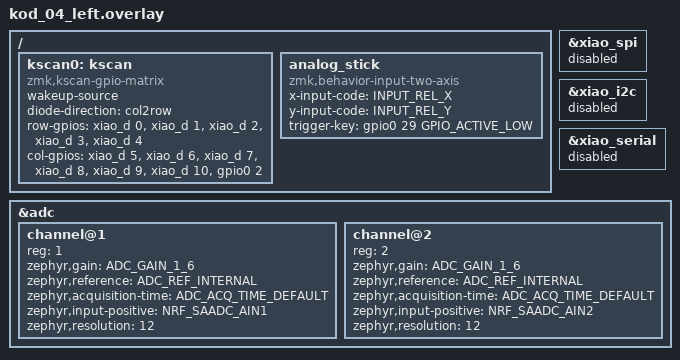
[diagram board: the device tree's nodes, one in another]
/*
 * Copyright (c) 2024 kodomari
 * SPDX-License-Identifier: MIT
 */

#include "kod_04.dtsi"

&xiao_spi { status = "disabled"; };
&xiao_i2c { status = "disabled"; };
&xiao_serial { status = "disabled"; };

/ {
    kscan0: kscan {
        compatible = "zmk,kscan-gpio-matrix";
        wakeup-source;
        diode-direction = "col2row";
        
        // 5行
        row-gpios
            = <&xiao_d 0 (GPIO_ACTIVE_HIGH | GPIO_PULL_DOWN)>
            , <&xiao_d 1 (GPIO_ACTIVE_HIGH | GPIO_PULL_DOWN)>
            , <&xiao_d 2 (GPIO_ACTIVE_HIGH | GPIO_PULL_DOWN)>
            , <&xiao_d 3 (GPIO_ACTIVE_HIGH | GPIO_PULL_DOWN)>
            , <&xiao_d 4 (GPIO_ACTIVE_HIGH | GPIO_PULL_DOWN)>
            ;
        
        // 7列
        col-gpios
            = <&xiao_d 5 GPIO_ACTIVE_HIGH>
            , <&xiao_d 6 GPIO_ACTIVE_HIGH>
            , <&xiao_d 7 GPIO_ACTIVE_HIGH>
            , <&xiao_d 8 GPIO_ACTIVE_HIGH>
            , <&xiao_d 9 GPIO_ACTIVE_HIGH>
            , <&xiao_d 10 GPIO_ACTIVE_HIGH>
            , <&gpio0 2 GPIO_ACTIVE_HIGH>  // P0.02 (A0/D0)
            ;
    };

    // アナログスティック（ジョイスティック）
    analog_stick {
        compatible = "zmk,behavior-input-two-axis";
        #binding-cells = <0>;
        x-input-code = <INPUT_REL_X>;
        y-input-code = <INPUT_REL_Y>;
        
        // 押しボタン（オプション）
        trigger-key = <&gpio0 29 GPIO_ACTIVE_LOW>;  // カステレーテッド P0.29
    };
};

// ADC設定（X軸、Y軸）
&adc {
    #address-cells = <1>;
    #size-cells = <0>;
    
    channel@1 {
        reg = <1>;
        zephyr,gain = "ADC_GAIN_1_6";
        zephyr,reference = "ADC_REF_INTERNAL";
        zephyr,acquisition-time = <ADC_ACQ_TIME_DEFAULT>;
        zephyr,input-positive = <NRF_SAADC_AIN1>;  // P0.03 (A1) - X軸
        zephyr,resolution = <12>;
    };
    
    channel@2 {
        reg = <2>;
        zephyr,gain = "ADC_GAIN_1_6";
        zephyr,reference = "ADC_REF_INTERNAL";
        zephyr,acquisition-time = <ADC_ACQ_TIME_DEFAULT>;
        zephyr,input-positive = <NRF_SAADC_AIN2>;  // P0.28 (A2) - Y軸
        zephyr,resolution = <12>;
    };
};
